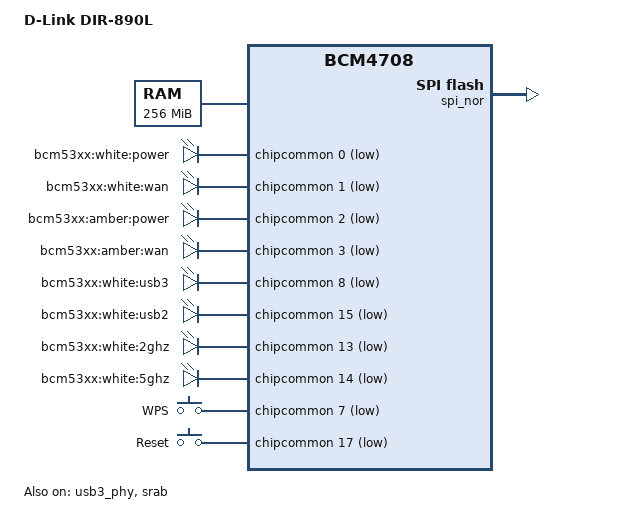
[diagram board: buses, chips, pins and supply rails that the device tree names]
/dts-v1/;
#include "bcm47094.dtsi"
#include "bcm5301x-nand-cs0-bch1.dtsi"
/ {
	compatible = "dlink,dir-890l", "brcm,bcm47094", "brcm,bcm4708";
	model = "D-Link DIR-890L";
	chosen {
		bootargs = "console=ttyS0,115200 earlycon";
	};
	memory@0 {
		device_type = "memory";
		reg = <0x00000000 0x08000000>,
		      <0x88000000 0x08000000>;
	};
	leds {
		compatible = "gpio-leds";
		led-power-white {
			label = "bcm53xx:white:power";
			gpios = <&chipcommon 0 GPIO_ACTIVE_LOW>;
			linux,default-trigger = "default-on";
		};
		led-wan-white {
			label = "bcm53xx:white:wan";
			gpios = <&chipcommon 1 GPIO_ACTIVE_LOW>;
		};
		led-power-amber {
			label = "bcm53xx:amber:power";
			gpios = <&chipcommon 2 GPIO_ACTIVE_LOW>;
		};
		led-wan-amber {
			label = "bcm53xx:amber:wan";
			gpios = <&chipcommon 3 GPIO_ACTIVE_LOW>;
		};
		led-usb3-white {
			label = "bcm53xx:white:usb3";
			gpios = <&chipcommon 8 GPIO_ACTIVE_LOW>;
			trigger-sources = <&xhci_port1>;
			linux,default-trigger = "usbport";
		};
		led-usb2-white {
			label = "bcm53xx:white:usb2";
			gpios = <&chipcommon 15 GPIO_ACTIVE_LOW>;
			trigger-sources = <&ohci_port1>, <&ehci_port1>;
			linux,default-trigger = "usbport";
		};
		led-2ghz {
			label = "bcm53xx:white:2ghz";
			gpios = <&chipcommon 13 GPIO_ACTIVE_LOW>;
		};
		led-5ghz {
			label = "bcm53xx:white:5ghz";
			gpios = <&chipcommon 14 GPIO_ACTIVE_LOW>;
		};
	};
	gpio-keys {
		compatible = "gpio-keys";
		button-wps {
			label = "WPS";
			linux,code = <KEY_WPS_BUTTON>;
			gpios = <&chipcommon 7 GPIO_ACTIVE_LOW>;
		};
		button-restart {
			label = "Reset";
			linux,code = <KEY_RESTART>;
			gpios = <&chipcommon 17 GPIO_ACTIVE_LOW>;
		};
	};
	nvram@1e1f0000 {
		compatible = "brcm,nvram";
		reg = <0x1e1f0000 0x00010000>;
		et0macaddr: et0macaddr {
		};
	};
};
&gmac2 {
	nvmem-cells = <&et0macaddr>;
	nvmem-cell-names = "mac-address";
};
&spi_nor {
	status = "okay";
};
&nandcs {
	partitions {
		compatible = "fixed-partitions";
		#address-cells = <1>;
		#size-cells = <1>;
		firmware@0 {
			compatible = "seama";
			label = "firmware";
			reg = <0x00000000 0x08000000>;
		};
	};
};
&usb2 {
	vcc-gpios = <&chipcommon 21 GPIO_ACTIVE_HIGH>;
};
&usb3 {
	vcc-gpios = <&chipcommon 18 GPIO_ACTIVE_HIGH>;
};
&usb3_phy {
	status = "okay";
};
&srab {
	status = "okay";
	ports {
		port@0 {
			label = "lan1";
		};
		port@1 {
			label = "lan2";
		};
		port@2 {
			label = "lan3";
		};
		port@3 {
			label = "lan4";
		};
		port@4 {
			label = "wan";
		};
		port@5 {
			status = "disabled";
		};
		port@7 {
			status = "disabled";
		};
		port@8 {
			label = "cpu";
			phy-mode = "rgmii";
		};
	};
};
